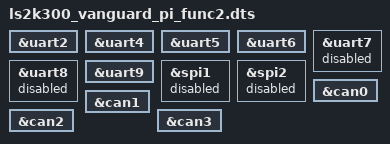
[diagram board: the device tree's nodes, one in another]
// SPDX-License-Identifier: GPL-2.0
/*
 * Copyright (C) 2025 Loongson Technology Corporation Limited
 */

/dts-v1/;

#include "ls2k300_vanguard_pi_common.dtsi"

&uart2 {
	status = "okay";
};

&uart4 {
	status = "okay";
};

&uart5 {
	status = "okay";
};

&uart6 {
	status = "okay";
};

&uart7 {
	status = "disabled";
};

&uart8 {
	status = "disabled";
};

&uart9 {
	status = "okay";
};

&spi1 {
	status = "disabled";
};

&spi2 {
	status = "disabled";
};

&can0 {
	status = "okay";
};

&can1 {
	status = "okay";
};

&can2 {
	status = "okay";
};

&can3 {
	status = "okay";
};
